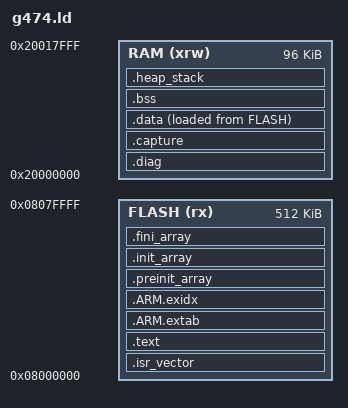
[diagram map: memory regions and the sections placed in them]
ENTRY(Reset_Handler)
MEMORY {
 FLASH (rx) : ORIGIN = 0x08000000, LENGTH = 512K
 RAM (xrw) : ORIGIN = 0x20000000, LENGTH = 96K
}
_estack = ORIGIN(RAM) + LENGTH(RAM);
SECTIONS {
 .isr_vector : { . = ALIGN(4); KEEP(*(.isr_vector)) } > FLASH
 .text : { *(.text*) *(.rodata*) KEEP(*(.init)) KEEP(*(.fini)) . = ALIGN(4); } > FLASH
 .ARM.extab : { *(.ARM.extab*) } > FLASH
 .ARM.exidx : { __exidx_start = .; *(.ARM.exidx*) __exidx_end = .; } > FLASH
 .preinit_array : { PROVIDE_HIDDEN(__preinit_array_start = .); KEEP(*(.preinit_array*)) PROVIDE_HIDDEN(__preinit_array_end = .); } > FLASH
 .init_array : { PROVIDE_HIDDEN(__init_array_start = .); KEEP(*(SORT(.init_array.*))) KEEP(*(.init_array*)) PROVIDE_HIDDEN(__init_array_end = .); } > FLASH
 .fini_array : { PROVIDE_HIDDEN(__fini_array_start = .); KEEP(*(SORT(.fini_array.*))) KEEP(*(.fini_array*)) PROVIDE_HIDDEN(__fini_array_end = .); } > FLASH
 .diag (NOLOAD) : { . = ALIGN(4); KEEP(*(.diag)) . = ALIGN(4); } > RAM
 .capture (NOLOAD) : { . = ALIGN(4); KEEP(*(.capture)) . = ALIGN(4); } > RAM
 _sidata = LOADADDR(.data);
 .data : { . = ALIGN(4); _sdata = .; *(.data*) . = ALIGN(4); _edata = .; } > RAM AT > FLASH
 .bss (NOLOAD) : { . = ALIGN(4); _sbss = .; *(.bss*) *(COMMON) . = ALIGN(4); _ebss = .; } > RAM
 .heap_stack (NOLOAD) : { . = ALIGN(8); PROVIDE(end = .); PROVIDE(_end = .); . += 0x200; . += 0x1800; } > RAM
 /DISCARD/ : { *(.note.GNU-stack) }
}
